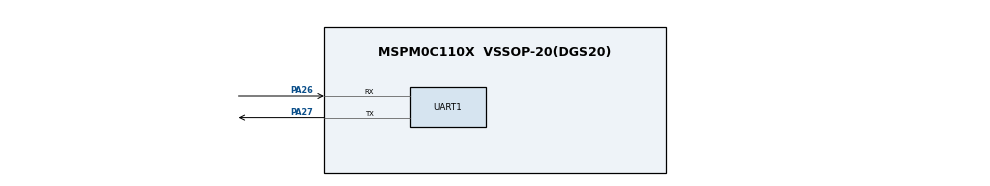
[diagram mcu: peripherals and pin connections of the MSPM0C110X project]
/**
 * @cliArgs --device "MSPM0C110X" --part "Default" --package "VSSOP-20(DGS20)" --product "mspm0_sdk@2.09.00.00"
 * @versions {"tool":"1.25.0+4268"}
 */

/**
 * Import the modules used in this configuration.
 */
const GPIO  = scripting.addModule("/ti/driverlib/GPIO", {}, false);
const GPIO1 = GPIO.addInstance();
const UART  = scripting.addModule("/ti/driverlib/UART", {}, false);
const UART1 = UART.addInstance();

/**
 * Write custom configuration values to the imported modules.
 */
GPIO1.$name                          = "GPIO_LEDS";
GPIO1.associatedPins.create(2);
GPIO1.associatedPins[0].$name        = "USER_LED_1";
GPIO1.associatedPins[0].initialValue = "SET";
GPIO1.associatedPins[0].assignedPin  = "22";
GPIO1.associatedPins[1].$name        = "USER_TEST";
GPIO1.associatedPins[1].assignedPin  = "2";
GPIO1.associatedPins[1].initialValue = "SET";

const Board           = scripting.addModule("/ti/driverlib/Board", {}, false);
Board.configureUnused = true;

const SYSCTL       = scripting.addModule("/ti/driverlib/SYSCTL", {}, false);
SYSCTL.powerPolicy = "STANDBY0";

UART1.$name                    = "UART_0";
UART1.rxFifoThreshold          = "DL_UART_RX_FIFO_LEVEL_ONE_ENTRY";
UART1.uartClkSrc               = "LFCLK";
UART1.ovsRate                  = "3";
UART1.parity                   = "ODD";
UART1.enabledInterrupts        = ["RX","TX"];
UART1.enableFIFO               = true;
UART1.txFifoThreshold          = "DL_UART_TX_FIFO_LEVEL_EMPTY";
UART1.peripheral.$assign       = "UART0";
UART1.peripheral.rxPin.$assign = "PA26";
UART1.peripheral.txPin.$assign = "PA27";
UART1.txPinConfig.$name        = "ti_driverlib_gpio_GPIOPinGeneric0";
UART1.rxPinConfig.$name        = "ti_driverlib_gpio_GPIOPinGeneric1";

/**
 * Pinmux solution for unlocked pins/peripherals. This ensures that minor changes to the automatic solver in a future
 * version of the tool will not impact the pinmux you originally saw.  These lines can be completely deleted in order to
 * re-solve from scratch.
 */
GPIO1.associatedPins[0].pin.$suggestSolution = "PA22";
GPIO1.associatedPins[1].pin.$suggestSolution = "PA2";
Board.peripheral.$suggestSolution            = "DEBUGSS";
Board.peripheral.swclkPin.$suggestSolution   = "PA20";
Board.peripheral.swdioPin.$suggestSolution   = "PA19";
SYSCTL.peripheral.$suggestSolution           = "SYSCTL";
